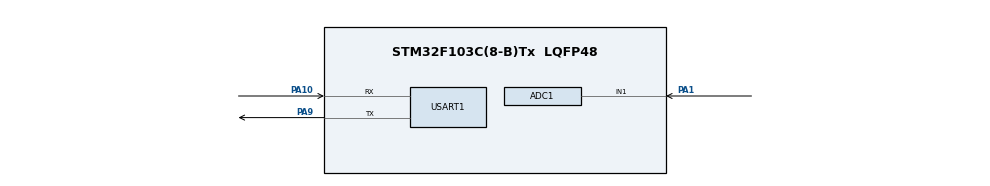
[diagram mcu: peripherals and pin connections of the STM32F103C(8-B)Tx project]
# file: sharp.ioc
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ADC1.Channel-0\#ChannelRegularConversion=ADC_CHANNEL_1
ADC1.NbrOfConversionFlag=1
ADC1.Rank-0\#ChannelRegularConversion=1
ADC1.SamplingTime-0\#ChannelRegularConversion=ADC_SAMPLETIME_1CYCLE_5
ADC1.master=1
Dma.Request0=USART1_RX
Dma.Request1=USART1_TX
Dma.USART1_RX.0.Direction=DMA_PERIPH_TO_MEMORY
Dma.USART1_RX.0.Instance=DMA1_Channel5
Dma.USART1_RX.0.MemDataAlignment=DMA_MDATAALIGN_BYTE
Dma.USART1_RX.0.MemInc=DMA_MINC_ENABLE
Dma.USART1_RX.0.Mode=DMA_NORMAL
Dma.USART1_RX.0.PeriphDataAlignment=DMA_PDATAALIGN_BYTE
Dma.USART1_RX.0.PeriphInc=DMA_PINC_DISABLE
Dma.USART1_RX.0.Priority=DMA_PRIORITY_LOW
Dma.USART1_TX.1.Direction=DMA_MEMORY_TO_PERIPH
Dma.USART1_TX.1.Instance=DMA1_Channel4
Dma.USART1_TX.1.MemDataAlignment=DMA_MDATAALIGN_BYTE
Dma.USART1_TX.1.MemInc=DMA_MINC_ENABLE
Dma.USART1_TX.1.Mode=DMA_NORMAL
Dma.USART1_TX.1.PeriphDataAlignment=DMA_PDATAALIGN_BYTE
Dma.USART1_TX.1.PeriphInc=DMA_PINC_DISABLE
Dma.USART1_TX.1.Priority=DMA_PRIORITY_LOW
Mcu.Family=STM32F1
Mcu.Name=STM32F103C(8-B)Tx
Mcu.Package=LQFP48
NVIC.DMA1_Channel4_IRQn=true\:0\:0\:false\:false\:true\:false\:true
NVIC.DMA1_Channel5_IRQn=true\:0\:0\:false\:false\:true\:false\:true
NVIC.PriorityGroup=NVIC_PRIORITYGROUP_4
NVIC.USART1_IRQn=true\:0\:0\:false\:false\:true\:true\:true
PA1.Signal=ADCx_IN1
PA10.Mode=Asynchronous
PA10.Signal=USART1_RX
PA13.Mode=Serial_Wire
PA13.Signal=SYS_JTMS-SWDIO
PA14.Mode=Serial_Wire
PA14.Signal=SYS_JTCK-SWCLK
PA9.Mode=Asynchronous
PA9.Signal=USART1_TX
PD0-OSC_IN.Mode=HSE-External-Oscillator
PD0-OSC_IN.Signal=RCC_OSC_IN
PD1-OSC_OUT.Mode=HSE-External-Oscillator
PD1-OSC_OUT.Signal=RCC_OSC_OUT
ProjectManager.HeapSize=0x200
ProjectManager.StackSize=0x400
ProjectManager.TargetToolchain=MDK-ARM V5.27
RCC.APB1Freq_Value=8000000
RCC.APB2Freq_Value=8000000
SH.ADCx_IN1.0=ADC1_IN1,IN1
USART1.VirtualMode=VM_ASYNC
board=custom

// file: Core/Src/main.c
/* USER CODE BEGIN Header */
/**
  ******************************************************************************
  * @file           : main.c
  * @brief          : Main program body
  ******************************************************************************
  * @attention
  *
  * <h2><center>&copy; Copyright (c) 2021 STMicroelectronics.
  * All rights reserved.</center></h2>
  *
  * This software component is licensed by ST under BSD 3-Clause license,
  * the "License"; You may not use this file except in compliance with the
  * License. You may obtain a copy of the License at:
  *                        opensource.org/licenses/BSD-3-Clause
  *
  ******************************************************************************
  */
/* USER CODE END Header */
#include "main.h"
#include "adc.h"
#include "dma.h"
#include "usart.h"
#include "gpio.h"

/* USER CODE BEGIN Includes */
#include "stdio.h"
#include "sharp.h"
//#include "Kalman.h"
/* USER CODE END Includes */

/* USER CODE BEGIN PV */
//extern Kalman kfp;
/* USER CODE END PV */

void SystemClock_Config(void);

/* USER CODE BEGIN 0 */
int fputc(int c,FILE *stream)
{
	uint8_t ch[1]={c};
	HAL_UART_Transmit(&huart1,ch,1,0xFFFF);
	return c;
}
/* USER CODE END 0 */

int main(void)
{
  /* USER CODE BEGIN 1 */
uint8_t adcx;
	float distance=0;
  /* USER CODE END 1 */

  /* MCU Configuration--------------------------------------------------------*/

  /* Reset of all peripherals, Initializes the Flash interface and the Systick. */
  HAL_Init();

  /* Configure the system clock */
  SystemClock_Config();

  /* Initialize all configured peripherals */
  MX_GPIO_Init();
  MX_DMA_Init();
  MX_ADC1_Init();
  MX_USART1_UART_Init();
  /* USER CODE BEGIN 2 */
//Kalman_Init();
  /* USER CODE END 2 */

  /* Infinite loop */
  while (1)
  {

    /* USER CODE BEGIN 3 */

//		KalmanFilter(&kfp,supersonic.distance);
//		printf("%f",supersonic.distance);
//		HAL_Delay(100);
//
		HAL_ADC_Start(&hadc1);
    adcx=HAL_ADC_GetValue(&hadc1);
		distance=ShuiWeiSensor_Get_Val();
		printf("adcX=%d\r\n",adcx);
		printf("distance=%f\r\n",distance);
		HAL_Delay(200);

	}
  /* USER CODE END 3 */
}

void SystemClock_Config(void)
{
  RCC_OscInitTypeDef RCC_OscInitStruct = {0};
  RCC_ClkInitTypeDef RCC_ClkInitStruct = {0};
  RCC_PeriphCLKInitTypeDef PeriphClkInit = {0};

  /** Initializes the RCC Oscillators according to the specified parameters
  * in the RCC_OscInitTypeDef structure.
  */
  RCC_OscInitStruct.OscillatorType = RCC_OSCILLATORTYPE_HSI;
  RCC_OscInitStruct.HSIState = RCC_HSI_ON;
  RCC_OscInitStruct.HSICalibrationValue = RCC_HSICALIBRATION_DEFAULT;
  RCC_OscInitStruct.PLL.PLLState = RCC_PLL_NONE;
  if (HAL_RCC_OscConfig(&RCC_OscInitStruct) != HAL_OK)
  {
    Error_Handler();
  }
  /** Initializes the CPU, AHB and APB buses clocks
  */
  RCC_ClkInitStruct.ClockType = RCC_CLOCKTYPE_HCLK|RCC_CLOCKTYPE_SYSCLK
                              |RCC_CLOCKTYPE_PCLK1|RCC_CLOCKTYPE_PCLK2;
  RCC_ClkInitStruct.SYSCLKSource = RCC_SYSCLKSOURCE_HSI;
  RCC_ClkInitStruct.AHBCLKDivider = RCC_SYSCLK_DIV1;
  RCC_ClkInitStruct.APB1CLKDivider = RCC_HCLK_DIV1;
  RCC_ClkInitStruct.APB2CLKDivider = RCC_HCLK_DIV1;

  if (HAL_RCC_ClockConfig(&RCC_ClkInitStruct, FLASH_LATENCY_0) != HAL_OK)
  {
    Error_Handler();
  }
  PeriphClkInit.PeriphClockSelection = RCC_PERIPHCLK_ADC;
  PeriphClkInit.AdcClockSelection = RCC_ADCPCLK2_DIV2;
  if (HAL_RCCEx_PeriphCLKConfig(&PeriphClkInit) != HAL_OK)
  {
    Error_Handler();
  }
}

void Error_Handler(void)
{
  __disable_irq();
  while (1)
  {
  }
}

/************************ (C) COPYRIGHT STMicroelectronics *****END OF FILE****/
